# NUC505_v1 register map
File version: 1.0
Registers are 32-bit, read-write, reset 0x0 unless marked. A register's access mark holds for its fields unless they carry their own. Offsets are from the block's base; [hi:lo] are bit positions; {n}, {i} and the like mark numbered series.

## RTC — RTC Register Map
Base 0x400E7000
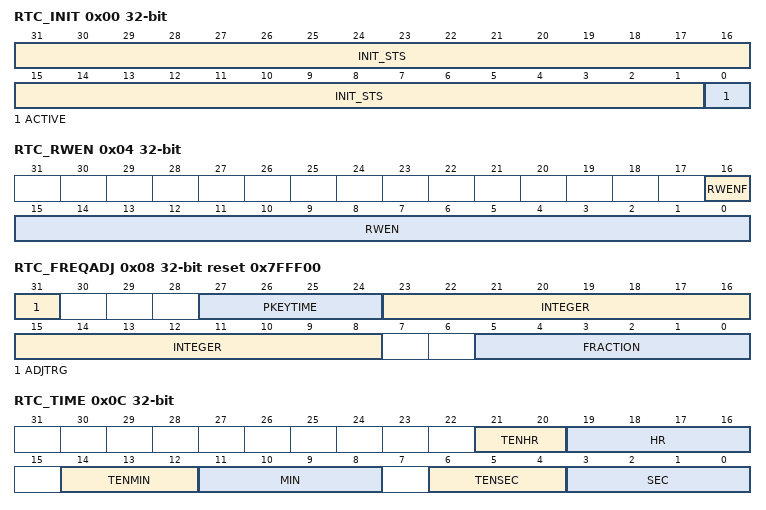
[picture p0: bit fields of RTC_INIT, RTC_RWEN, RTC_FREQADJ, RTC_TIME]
0x00 RTC_INIT — RTC Initiation Register
  [31:1] INIT_STS — RTC Initiation (While Writing). When RTC block is powered on, RTC is at reset state. User has to write a number (0x a5eb1357) to INIT to make RTC exit from reset state. Once the INIT is written as 0xa5eb1357, the RTC will be in un-reset state permanently. The INIT is a write-only field and read value will be always "0". . RTC Internal Status (While Reading) [31:8]: INIT[31:8] [7:5]: RTC internal state machine of key detection [4]: Status of power key, 0:pressed and 1:released [3]: Status of power off request pwr_key_off [2]: Level shifter reset [1]: Level shifter enable
  [0] ACTIVE ro — RTC Active Status (Read Only)
    0=RTC is at reset state; 1=RTC is at normal active state
0x04 RTC_RWEN — RTC Access Enable Register
  [16] RWENF ro — RTC Register Access Enable Flag (Read Only). Note: This bit will be set after RTC_RWEN[15:0] register is load a 0xA965, and it will be cleared when RTC_RWEN[15:0] is not 0xA965.
    0=RTC register access Disabled; 1=RTC register access Enabled
  [15:0] RWEN — RTC Register Access Enable Password (R/W)
    0xA965=Access Password
0x08 RTC_FREQADJ reset 0x7FFF00 — RTC Frequency Compensation Register
  [31] ADJTRG — RTC Clock Calibration Control. This bit will be kept at "High" while the calibration is ongoing and cleared to "Low" automatically while the calibration is done and the content of RTC_CALCNT register is valid calibration flow as follows.
    0=RTC Clock calibration mechanism Disabled; 1=RTC Clock calibration mechanism Enabled
  [27:24] PKEYTIME — Minimum Duration That Power Key Must Be Pressed to Turn on Core Power
  [23:8] INTEGER — Integer Part
  [5:0] FRACTION — Fraction Part. Digit in RTC_FREQADJ must be expressed as hexadecimal number.
0x0C RTC_TIME — RTC Time Loading Register
  [21:20] TENHR — 10-Hour Time Digit
  [19:16] HR — 1-Hour Time Digit
  [14:12] TENMIN — 10-Min Time Digit
  [11:8] MIN — 1-Min Time Digit
  [6:4] TENSEC — 10-Sec Time Digit
  [3:0] SEC — 1-Sec Time Digit
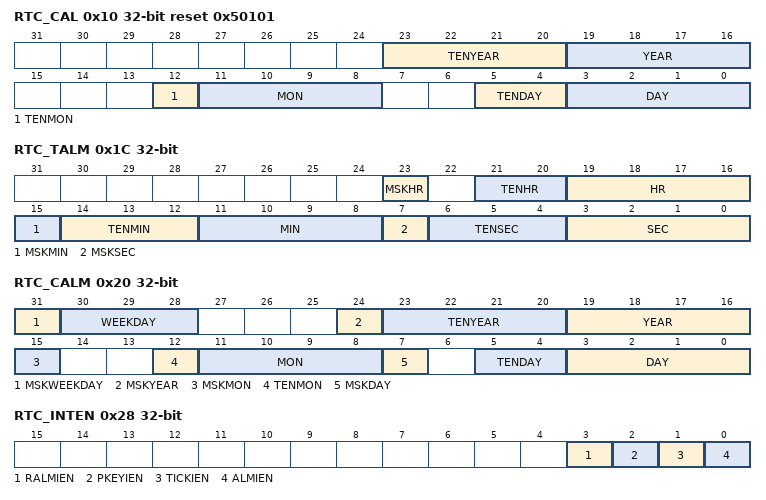
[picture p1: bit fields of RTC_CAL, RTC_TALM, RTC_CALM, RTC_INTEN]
0x10 RTC_CAL reset 0x50101 — RTC Calendar Loading Register
  [23:20] TENYEAR — 10-Year Calendar Digit
  [19:16] YEAR — 1-Year Calendar Digit
  [12] TENMON — 10-Month Calendar Digit
  [11:8] MON — 1-Month Calendar Digit
  [5:4] TENDAY — 10-Day Calendar Digit
  [3:0] DAY — 1-Day Calendar Digit
0x14 RTC_CLKFMT reset 0x1 — RTC Time Scale Selection Register
  [0] _24HEN — 24-hour / 12-hour Mode Selection. Indicate that RTC_TIME and RTC_TALM are in 24-hour mode or 12-hour mode.
    0=12-hour time scale with AM and PM indication selected; 1=24-hour time scale selected
0x18 RTC_WEEKDAY reset 0x6 — RTC Day of the Week Register
  [2:0] WEEKDAY — Day of the Week Register
    0=Sunday; 1=Monday; 2=Tuesday; 3=Wednesday; 4=Thursday; 5=Friday; 6=Saturday
0x1C RTC_TALM — RTC Time Alarm Register
  [23] MSKHR — Mask Alarm by Hour
    0=Activate; 1=Mask
  [21:20] TENHR — 10-hour Time Digit of Alarm Setting (0-2). When RTC runs as 12-hour time scale mode, RTC_TIME[21] (the high bit of TENHR[1:0]) means AM/PM indication. (If RTC_TIME[21] is 1, it indicates PM time message.)
  [19:16] HR — 1-Hour Time Digit of Alarm Setting (0-9)
  [15] MSKMIN — Mask Alarm by Minute
    0=Activate; 1=Mask
  [14:12] TENMIN — 10-Min Time Digit of Alarm Setting (0-5)
  [11:8] MIN — 1-Min Time Digit of Alarm Setting (0-9)
  [7] MSKSEC — Mask Alarm by Second
    0=Activate; 1=Mask
  [6:4] TENSEC — 10-Sec Time Digit of Alarm Setting (0-5)
  [3:0] SEC — 1-Sec Time Digit of Alarm Setting (0-9)
0x20 RTC_CALM — RTC Calendar Alarm Register
  [31] MSKWEEKDAY — Mask Alarm by Week Day
    0=Activate; 1=Mask
  [30:28] WEEKDAY — Week Day Alarm Digit
  [24] MSKYEAR — Mask Alarm by Year
    0=Activate; 1=Mask
  [23:20] TENYEAR — 10-Year Calendar Digit of Alarm Setting (0-9)
  [19:16] YEAR — 1-Year Calendar Digit of Alarm Setting (0-9)
  [15] MSKMON — Mask Alarm by Month
    0=Activate; 1=Mask
  [12] TENMON — 10-Month Calendar Digit of Alarm Setting (0-1)
  [11:8] MON — 1-Month Calendar Digit of Alarm Setting (0-9)
  [7] MSKDAY — Mask Alarm by Day
    0=Activate; 1=Mask
  [5:4] TENDAY — 10-Day Calendar Digit of Alarm Setting (0-3)
  [3:0] DAY — 1-Day Calendar Digit of Alarm Setting (0-9)
0x24 RTC_LEAPYEAR ro — RTC Leap Year Indication Register
  [0] LEAPYEAR — Leap Year Indication Register (Read Only)
    0=This year is not a leap year; 1=This year is leap year
0x28 RTC_INTEN — RTC Interrupt Enable Register
  [3] RALMIEN — Relative Alarm Interrupt Enable Control
    0=RTC Relative Alarm Interrupt Disabled; 1=RTC Relative Alarm Interrupt Enabled
  [2] PKEYIEN — Power Switch Interrupt Enable Control
    0=Power Switch Be Pressed Interrupt Disabled; 1=Power Switch Be Pressed Interrupt Enabled
  [1] TICKIEN — Time Tick Interrupt Enable Control
    0=RTC Time Tick Interrupt and counter Disabled; 1=RTC Time Tick Interrupt and counter Enabled
  [0] ALMIEN — Alarm Interrupt Enable Control
    0=RTC Alarm Interrupt Disabled; 1=RTC Alarm Interrupt Enabled
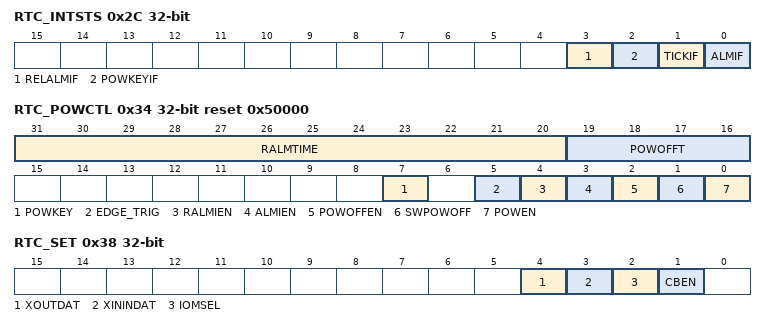
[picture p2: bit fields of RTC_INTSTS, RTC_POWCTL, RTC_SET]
0x2C RTC_INTSTS — RTC Interrupt Indication Register
  [3] RELALMIF — RTC Relative Alarm Interrupt Indication. Note: Software can also clear this bit after RTC interrupt has occurred
    0=Relative alarm interrupt never occurred; 1=Relative time counter and calendar counter have counted to a specified time recorded in RTC_TALM and RTC_CALM. RTC alarm interrupt has been activated
  [2] POWKEYIF — Power Switch Interrupt Flag. When RTC detect power key (RTC_nRWAKE) is pressed , the POWKEYIF (RTC_INTSYS[2]) is set to 1. Note: Software can also clear this bit after RTC interrupt has occurred
    0=The power switch interrupt never occurred; 1=The power switch has been activated
  [1] TICKIF — RTC Time Tick Interrupt Flag. When RTC time tick happened, this bit will be set to 1 and an interrupt will be generated if RTC Tick Interrupt enabled TICKIEN (RTC_INTEN[1]) is set to 1. Chip will also be woken up if RTC Tick Interrupt is enabled and this bit is set to 1 when chip is running at Power-down mode. Note: Write 1 to clear to clear this bit.
    0=Tick condition does not occur; 1=Tick condition occur
  [0] ALMIF — RTC Alarm Interrupt Flag. When RTC time counters RTC_TIME and RTC_CAL match the alarm setting time registers RTC_TALM and RTC_CALM, this bit will be set to 1 and an interrupt will be generated if RTC Alarm Interrupt enabled ALMIEN (RTC_INTEN[0]) is set to 1. Chip will be woken up if RTC Alarm Interrupt is enabled when chip is at Power-down mode. Note: Write 1 to clear this bit.
    0=Alarm condition is not matched; 1=Alarm condition is matched
0x30 RTC_TICK — RTC Time Tick Register
  [2:0] TICKSEL — Time Tick Register. These bits are used to select RTC time tick period for Periodic Time Tick Interrupt request.
    0=Time tick is 1 second; 1=Time tick is 1/2 second; 2=Time tick is 1/4 second; 3=Time tick is 1/8 second; 4=Time tick is 1/16 second; 5=Time tick is 1/32 second; 6=Time tick is 1/64 second; 7=Time tick is 1/28 second
0x34 RTC_POWCTL reset 0x50000 — RTC Power Time-out Register
  [31:20] RALMTIME — Relative Time Alarm Period (Second Unit). Indicates the period of the relative time alarm. Its maximum value is 1800.
  [19:16] POWOFFT — Power Clear Period. Indicates that the period of the power core will be cleared after the power key is pressed. Its time scalar is one second so that the default is 5 second.
  [7] POWKEY — Power Key Status
    0=The power key is pressed to low; 1=The power key status is high
  [5] EDGE_TRIG — Power Key Trigger Mode
    0=LEVEL TRIGGER, RTC is powered on while power key is pressed longer programmed duration; 1=EDGE TRIGE, RTC is powered on while power key is pressed longer than programmed duration and then released
  [4] RALMIEN — Relative Time Alarm
    0=The relative time alarm control Disabled; 1=The relative time alarm control Enabled
  [3] ALMIEN — Normal Time Alarm
    0=Normal time alarm control Disabled; 1=Normal time alarm control Enabled
  [2] POWOFFEN — Hardware Power Clear Enable Control
    0=The RTC_RPWR pin will not be influenced by the pressed time of power key; 1=The RTC_RPWR pin will be cleared to low when the power key is pressed over the POWOFFT second
  [1] SWPOWOFF — Software Core Power Disable Control. If the power key is pressed, the RTC_RPWR pin can be cleared by setting this bit and this can be cleared to 0 when the pressed power key, RTC_RPWR is released. If the power is not pressed, it is not used to set this bit.
    1=Force the RTC_RPWR to low
  [0] POWEN — Power ON. RTC_RPWR will change to high state when POWEN value change from 0 to 1. Note: The following conditions will make RTC_RPWR low: Set POWEN bit to 0. POWOFFEN is set to 1 and the power key is pressed over the period of POWOFFT. This bit can be read back after the RTC enable is active.
0x38 RTC_SET — RTC Setting Register
  [4] XOUTDAT ro — X32_OUT PAD Status
  [3] XININDAT ro — X32_IN PAD Status
  [2] IOMSEL — X32_IN and X32_OUT PAD Digital Input Mode Control
    0=Digital input mode; 1=Crystal mode (default value)
  [1] CBEN — 32768 Hz (LXT) Crystal Control
    0=Crystal Disabled; 1=Crystal Enabled
0x3C RTC_CLKSRC reset 0x1 — RC Oscillator Setting Register
  [0] CKSRC — Internal RC Oscillator Control
    0=Internal RC oscillator Disabled; 1=Internal RC oscillator Enabled
0x40 RTC_CALCNT ro — RC Oscillator Calibration Register
  [31:0] CALCNT — Cycle Number of PCLK During 1Hz. That is generated by dividing RTC Clock. This number can be used to deduct the real clock rate of RTC clock.
0x44 RTC_SYNC ro — RTC Register Write Complete
  [0] SYNC — Polling the Flag to Detect RTC Register Write Complete
    0=Register cannot be written; 1=Register can be written because write complete
{0x54+4i} RTC_SPR{i} (i=0..7) — RTC Spare Register {i}
  [31:0] RTC_SPRn — RTC Spare Register
